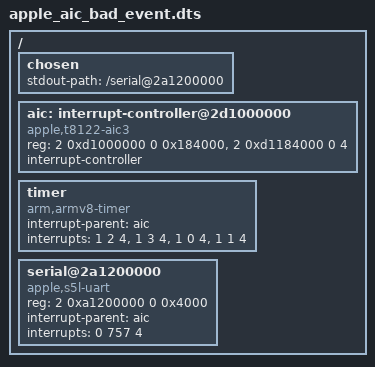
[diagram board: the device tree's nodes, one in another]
// Copyright 2026 The Fuchsia Authors. All rights reserved.
// Use of this source code is governed by a BSD-style license that can be
// found in the LICENSE file.

/dts-v1/;
/ {
    #address-cells = <2>;
    #size-cells = <2>;
    chosen { stdout-path = "/serial@2a1200000"; };
    aic: interrupt-controller@2d1000000 {
        compatible = "apple,t8122-aic3";
        reg = <2 0xd1000000 0 0x184000>, <2 0xd1184000 0 4>;
        reg-names = "core", "event";
        interrupt-controller;
        #interrupt-cells = <3>;
        #address-cells = <0>;
    };
    timer {
        compatible = "arm,armv8-timer";
        interrupt-parent = <&aic>;
        interrupt-names = "phys", "virt", "hyp-phys", "hyp-virt";
        interrupts = <1 2 4>, <1 3 4>, <1 0 4>, <1 1 4>;
    };
    serial@2a1200000 {
        compatible = "apple,s5l-uart";
        reg = <2 0xa1200000 0 0x4000>;
        interrupt-parent = <&aic>;
        interrupts = <0 757 4>;
    };
};
